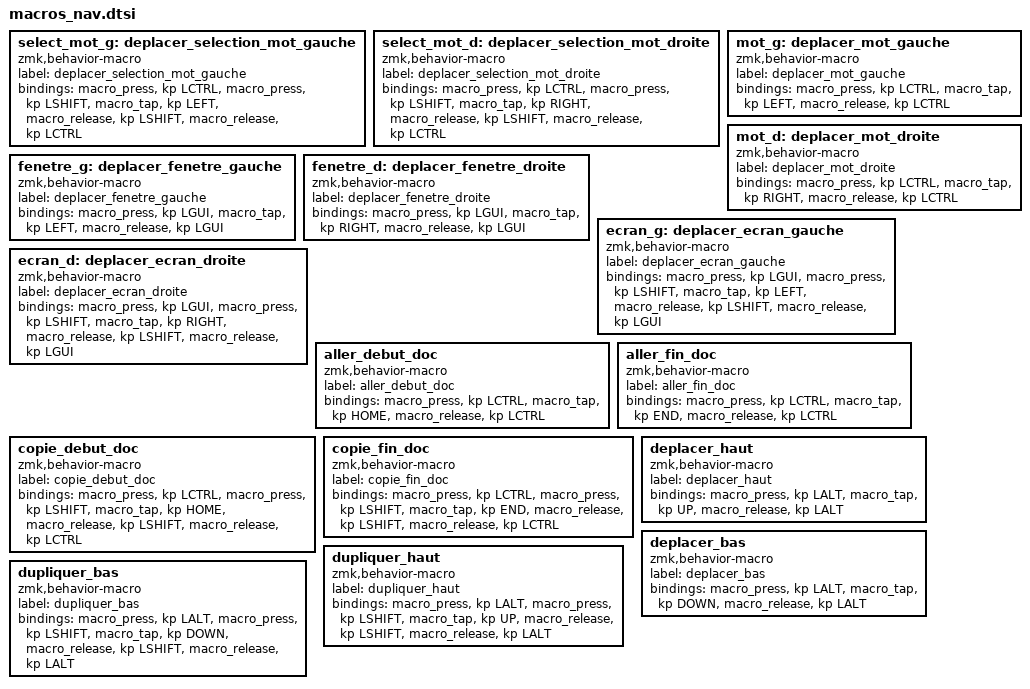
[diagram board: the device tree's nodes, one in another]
// ===========================
// ======= Main gauche =======
// ===========================



select_mot_g: deplacer_selection_mot_gauche {
	compatible = "zmk,behavior-macro";
	label = "deplacer_selection_mot_gauche";
	#binding-cells = <0>;
	bindings
		= <&macro_press 	&kp LCTRL>
		, <&macro_press 	&kp LSHIFT>
		, <&macro_tap 		&kp LEFT>
		, <&macro_release 	&kp LSHIFT>
		, <&macro_release 	&kp LCTRL>
	;
};

select_mot_d: deplacer_selection_mot_droite {
	compatible = "zmk,behavior-macro";
	label = "deplacer_selection_mot_droite";
	#binding-cells = <0>;
	bindings
		= <&macro_press 	&kp LCTRL>
		, <&macro_press 	&kp LSHIFT>
		, <&macro_tap 		&kp RIGHT>
		, <&macro_release 	&kp LSHIFT>
		, <&macro_release 	&kp LCTRL>
	;
};



mot_g: deplacer_mot_gauche {
	compatible = "zmk,behavior-macro";
	label = "deplacer_mot_gauche";
	#binding-cells = <0>;
	bindings
		= <&macro_press 	&kp LCTRL>
		, <&macro_tap 		&kp LEFT>
		, <&macro_release 	&kp LCTRL>
	;
};

mot_d: deplacer_mot_droite {
	compatible = "zmk,behavior-macro";
	label = "deplacer_mot_droite";
	#binding-cells = <0>;
	bindings
		= <&macro_press 	&kp LCTRL>
		, <&macro_tap 		&kp RIGHT>
		, <&macro_release 	&kp LCTRL>
	;
};



fenetre_g: deplacer_fenetre_gauche {
	compatible = "zmk,behavior-macro";
	label = "deplacer_fenetre_gauche";
	#binding-cells = <0>;
	bindings
		= <&macro_press 	&kp LGUI>
		, <&macro_tap 	  	&kp LEFT>
		, <&macro_release 	&kp LGUI>
	;
};

fenetre_d: deplacer_fenetre_droite {
	compatible = "zmk,behavior-macro";
	label = "deplacer_fenetre_droite";
	#binding-cells = <0>;
	bindings
		= <&macro_press 	&kp LGUI>
		, <&macro_tap 	  	&kp RIGHT>
		, <&macro_release 	&kp LGUI>
	;
};



ecran_g: deplacer_ecran_gauche {
	compatible = "zmk,behavior-macro";
	label = "deplacer_ecran_gauche";
	#binding-cells = <0>;
	bindings
		= <&macro_press 	&kp LGUI>
		, <&macro_press 	&kp LSHIFT>
		, <&macro_tap 	  	&kp LEFT>
		, <&macro_release 	&kp LSHIFT>
		, <&macro_release 	&kp LGUI>
	;
};

ecran_d: deplacer_ecran_droite {
	compatible = "zmk,behavior-macro";
	label = "deplacer_ecran_droite";
	#binding-cells = <0>;
	bindings
		= <&macro_press 	&kp LGUI>
		, <&macro_press 	&kp LSHIFT>
		, <&macro_tap 	  	&kp RIGHT>
		, <&macro_release 	&kp LSHIFT>
		, <&macro_release 	&kp LGUI>
	;
};







// ===========================
// ======= Main droite =======
// ===========================



aller_debut_doc: aller_debut_doc {
	compatible = "zmk,behavior-macro";
	label = "aller_debut_doc";
	#binding-cells = <0>;
	bindings
		= <&macro_press 	&kp LCTRL>
		, <&macro_tap 		&kp HOME>
		, <&macro_release 	&kp LCTRL>
	;
};

aller_fin_doc: aller_fin_doc {
	compatible = "zmk,behavior-macro";
	label = "aller_fin_doc";
	#binding-cells = <0>;
	bindings
		= <&macro_press		&kp LCTRL>
		, <&macro_tap 		&kp END>
		, <&macro_release 	&kp LCTRL>
	;
};



copie_debut_doc: copie_debut_doc {
	compatible = "zmk,behavior-macro";
	label = "copie_debut_doc";
	#binding-cells = <0>;
	bindings
		= <&macro_press 	&kp LCTRL>
		, <&macro_press 	&kp LSHIFT>
		, <&macro_tap 	  	&kp HOME>
		, <&macro_release 	&kp LSHIFT>
		, <&macro_release 	&kp LCTRL>
	;
};

copie_fin_doc: copie_fin_doc {
	compatible = "zmk,behavior-macro";
	label = "copie_fin_doc";
	#binding-cells = <0>;
	bindings
		= <&macro_press 	&kp LCTRL>
		, <&macro_press 	&kp LSHIFT>
		, <&macro_tap 	  	&kp END>
		, <&macro_release 	&kp LSHIFT>
		, <&macro_release 	&kp LCTRL>
	;
};



deplacer_haut: deplacer_haut {
	compatible = "zmk,behavior-macro";
	label = "deplacer_haut";
	#binding-cells = <0>;
	bindings
		= <&macro_press 	&kp LALT>
		, <&macro_tap 	  	&kp UP>
		, <&macro_release 	&kp LALT>
	;
};

deplacer_bas: deplacer_bas {
	compatible = "zmk,behavior-macro";
	label = "deplacer_bas";
	#binding-cells = <0>;
	bindings
		= <&macro_press 	&kp LALT>
		, <&macro_tap 	  	&kp DOWN>
		, <&macro_release 	&kp LALT>
	;
};



dupliquer_haut: dupliquer_haut {
	compatible = "zmk,behavior-macro";
	label = "dupliquer_haut";
	#binding-cells = <0>;
	bindings
		= <&macro_press 	&kp LALT>
		, <&macro_press 	&kp LSHIFT>
		, <&macro_tap 	  	&kp UP>
		, <&macro_release 	&kp LSHIFT>
		, <&macro_release 	&kp LALT>
	;
};

dupliquer_bas: dupliquer_bas {
	compatible = "zmk,behavior-macro";
	label = "dupliquer_bas";
	#binding-cells = <0>;
	bindings
		= <&macro_press 	&kp LALT>
		, <&macro_press 	&kp LSHIFT>
		, <&macro_tap 	  	&kp DOWN>
		, <&macro_release 	&kp LSHIFT>
		, <&macro_release 	&kp LALT>
	;
};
